# DDR32SS0_CTLPHY_WRAP_CTL_CFG_CTLCFG register map
Vendor: Texas Instruments
Registers are 32-bit, read-write, reset 0x0 unless marked. A register's access mark holds for its fields unless they carry their own. Offsets are as the file gives them; [hi:lo] are bit positions; lines under a group give offsets from that group; {n}, {i} and the like mark numbered series.

## DDR32SS0_CTLPHY_WRAP_CTL_CFG_CTLCFG (part 3 of 11)
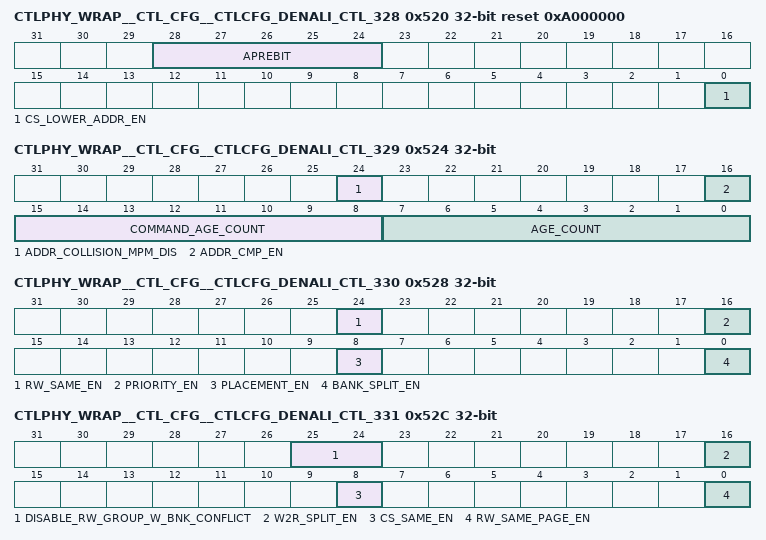
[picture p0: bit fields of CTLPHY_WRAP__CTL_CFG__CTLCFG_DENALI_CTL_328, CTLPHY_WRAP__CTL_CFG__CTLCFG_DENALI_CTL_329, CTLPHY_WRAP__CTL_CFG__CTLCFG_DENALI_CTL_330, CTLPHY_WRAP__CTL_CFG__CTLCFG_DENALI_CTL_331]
0x520 CTLPHY_WRAP__CTL_CFG__CTLCFG_DENALI_CTL_328 reset 0xA000000
  [28:24] APREBIT — Location of the auto pre-charge bit in the DRAM address.
  [0] CS_LOWER_ADDR_EN — Enables moving the CS field to lower in the address map. When set to 1, the memory address map will be changed to ROW__CS__BANK. Please refer to the limitations before setting this bit.
0x524 CTLPHY_WRAP__CTL_CFG__CTLCFG_DENALI_CTL_329
  [24] ADDR_COLLISION_MPM_DIS — Disable address collision detection extension using micro page mask for command queue placement and selection. Set to 1 to disable.
  [16] ADDR_CMP_EN — Enable address collision detection as a rule for command queue placement. Set to 1 to enable.
  [15:8] COMMAND_AGE_COUNT — Initial value of individual command aging counters for command aging.
  [7:0] AGE_COUNT — Initial value of controller aging-rate counter for command aging.
0x528 CTLPHY_WRAP__CTL_CFG__CTLCFG_DENALI_CTL_330
  [24] RW_SAME_EN — Enable read/write grouping as a rule for command queue placement. Set to 1 to enable.
  [16] PRIORITY_EN — Enable priority as a rule for command queue placement. Set to 1 to enable.
  [8] PLACEMENT_EN — Enable placement logic for command queue. Set to 1 to enable.
  [0] BANK_SPLIT_EN — Enable bank splitting as a rule for command queue placement. Set to 1 to enable.
0x52C CTLPHY_WRAP__CTL_CFG__CTLCFG_DENALI_CTL_331
  [25:24] DISABLE_RW_GROUP_W_BNK_CONFLICT — Disables placement to read/write group when grouping creates a bank collision. Bit [0] controls placement next to bank conflict command and bit [1] controls placement 2 away from bank conflict command. Set each bit to 1 to disable.
  [16] W2R_SPLIT_EN — Enable splitting of commands to the same chip select from a write to a read command as a rule for command queue placement.
  [8] CS_SAME_EN — Enable chip select grouping when read/write grouping as a rule for command queue placement. This is only valid when the RW_SAME_EN parameter is set. Set to 1 to enable.
  [0] RW_SAME_PAGE_EN — Enable page grouping when read/write grouping as a rule for command queue placement. This is only valid when the RW_SAME_EN parameter is set. Set to 1 to enable.
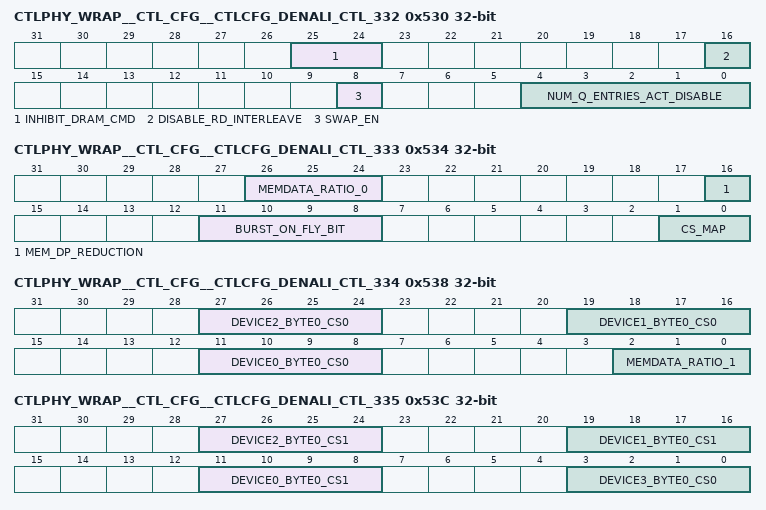
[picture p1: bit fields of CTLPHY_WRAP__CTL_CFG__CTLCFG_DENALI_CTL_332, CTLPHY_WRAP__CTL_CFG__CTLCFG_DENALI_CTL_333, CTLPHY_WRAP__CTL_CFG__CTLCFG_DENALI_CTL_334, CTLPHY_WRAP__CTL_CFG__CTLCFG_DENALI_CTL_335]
0x530 CTLPHY_WRAP__CTL_CFG__CTLCFG_DENALI_CTL_332
  [25:24] INHIBIT_DRAM_CMD — Inhibit command types from being executed from the command queue. Clear to 0 to enable any command, program to 1 to inhibit read/write and bank commands, program to 2 to inhibit MRR and peripheral MRR commands, or program to 3 to inhibit MRR and read/write commands.
  [16] DISABLE_RD_INTERLEAVE — Disable read data interleaving for commands from the same port, regardless of the requestor ID.
  [8] SWAP_EN — Enable command swapping logic in execution unit. Set to 1 to enable.
  [4:0] NUM_Q_ENTRIES_ACT_DISABLE — Number of queue entries in which ACT requests will be disabled. Programming to X will disable ACT requests from the X entries lowest in the command queue.
0x534 CTLPHY_WRAP__CTL_CFG__CTLCFG_DENALI_CTL_333
  [26:24] MEMDATA_RATIO_0 — Defines the ratio of the DRAM device size on chip select 0 to the memory data width. Program with the log2 ratio of the memory data width to the device data width. CS=0
  [16] MEM_DP_REDUCTION — Enable the half datapath feature of the controller. Set to 1 to enable.
  [11:8] BURST_ON_FLY_BIT — Identifies the burst-on-fly bit in the memory mode registers.
  [1:0] CS_MAP — Defines which chip selects are active.
0x538 CTLPHY_WRAP__CTL_CFG__CTLCFG_DENALI_CTL_334
  [27:24] DEVICE2_BYTE0_CS0 — Defines the byte location of byte0 in the memory datapath for device 2 on chip 0. Used for MRRs to identify where data will be returned. DEV=2
  [19:16] DEVICE1_BYTE0_CS0 — Defines the byte location of byte0 in the memory datapath for device 1 on chip 0. Used for MRRs to identify where data will be returned. DEV=1
  [11:8] DEVICE0_BYTE0_CS0 — Defines the byte location of byte0 in the memory datapath for device 0 on chip 0. Used for MRRs to identify where data will be returned. DEV=0
  [2:0] MEMDATA_RATIO_1 — Defines the ratio of the DRAM device size on chip select 1 to the memory data width. Program with the log2 ratio of the memory data width to the device data width. CS=1
0x53C CTLPHY_WRAP__CTL_CFG__CTLCFG_DENALI_CTL_335
  [27:24] DEVICE2_BYTE0_CS1 — Defines the byte location of byte0 in the memory datapath for device 2 on chip 1. Used for MRRs to identify where data will be returned. DEV=2
  [19:16] DEVICE1_BYTE0_CS1 — Defines the byte location of byte0 in the memory datapath for device 1 on chip 1. Used for MRRs to identify where data will be returned. DEV=1
  [11:8] DEVICE0_BYTE0_CS1 — Defines the byte location of byte0 in the memory datapath for device 0 on chip 1. Used for MRRs to identify where data will be returned. DEV=0
  [3:0] DEVICE3_BYTE0_CS0 — Defines the byte location of byte0 in the memory datapath for device 3 on chip 0. Used for MRRs to identify where data will be returned. DEV=3
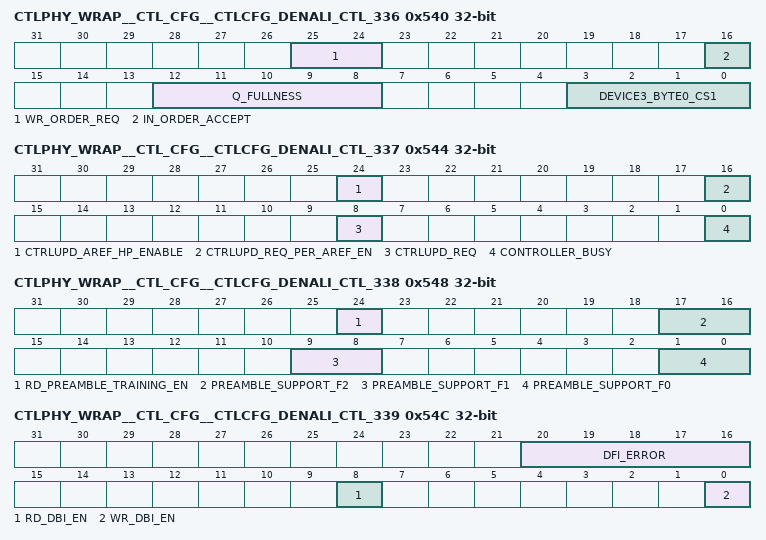
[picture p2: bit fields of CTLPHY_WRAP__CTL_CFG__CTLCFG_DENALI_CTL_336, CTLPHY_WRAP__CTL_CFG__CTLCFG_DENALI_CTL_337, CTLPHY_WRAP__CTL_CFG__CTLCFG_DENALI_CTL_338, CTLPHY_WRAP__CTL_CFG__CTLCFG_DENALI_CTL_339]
0x540 CTLPHY_WRAP__CTL_CFG__CTLCFG_DENALI_CTL_336
  [25:24] WR_ORDER_REQ — Determines if the controller can re-order write commands from the same source ID and/or the same port. Bit [0] controls source ID usage and bit [1] controls port ID usage. Set each bit to 1 to enable usage in placement logic.
  [16] IN_ORDER_ACCEPT — Forces the controller to accept commands in the order in which they are placed in the command queue.
  [12:8] Q_FULLNESS — Quantity that determines when the command queue almost full signal will assert [q_almost_full]. When cleared to 0, the q_almost_full signal will be driven to 0 irrespective of number of entries in the command queue.
  [3:0] DEVICE3_BYTE0_CS1 — Defines the byte location of byte0 in the memory datapath for device 3 on chip 1. Used for MRRs to identify where data will be returned. DEV=3
0x544 CTLPHY_WRAP__CTL_CFG__CTLCFG_DENALI_CTL_337 access per field
  [24] CTRLUPD_AREF_HP_ENABLE rw — Enable an automatic controller-initiated update [dfi_ctrlupd_req] after every high priority refresh when executing as a subtask request. Set to 1 to enable.
  [16] CTRLUPD_REQ_PER_AREF_EN rw — Enable an automatic controller-initiated update [dfi_ctrlupd_req] after every refresh. Set to 1 to enable.
  [8] CTRLUPD_REQ wo — Assert the DFI controller-initiated update request signal dfi_ctrlupd_req. Set to 1 to trigger. WRITE-ONLY
  [0] CONTROLLER_BUSY ro — Indicator that the controller is processing a command. Evaluates all ports for outstanding transactions. Value of 1 indicates controller busy. READ-ONLY
0x548 CTLPHY_WRAP__CTL_CFG__CTLCFG_DENALI_CTL_338
  [24] RD_PREAMBLE_TRAINING_EN — Enable read preamble training during gate training. Set to 1 to enable.
  [17:16] PREAMBLE_SUPPORT_F2 — Selection the preamble for read and write burst transfers. FC=2
  [9:8] PREAMBLE_SUPPORT_F1 — Selection the preamble for read and write burst transfers. FC=1
  [1:0] PREAMBLE_SUPPORT_F0 — Selection the preamble for read and write burst transfers. FC=0
0x54C CTLPHY_WRAP__CTL_CFG__CTLCFG_DENALI_CTL_339 access per field
  [20:16] DFI_ERROR ro — Indicates that the DFI error flag has been asserted. READ-ONLY
  [8] RD_DBI_EN rw — Enables controller support of DRAM DBI feature for read data with DDR4 devices. Set to 1 to enable.
  [0] WR_DBI_EN rw — Enables controller support of DRAM DBI feature for write data with DDR4 devices. Set to 1 to enable.
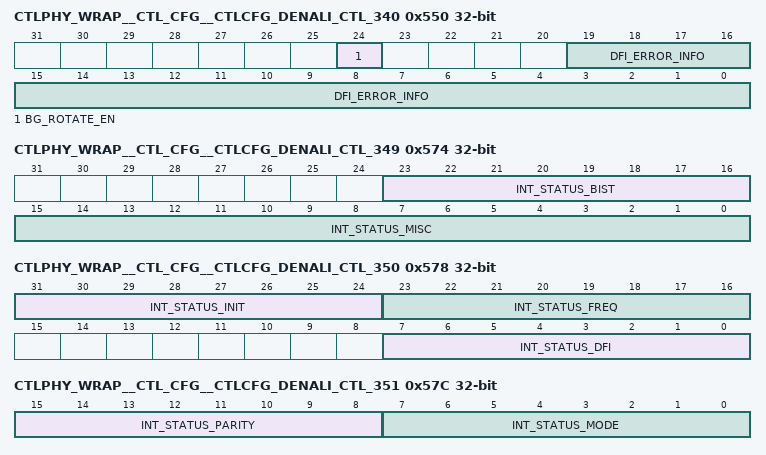
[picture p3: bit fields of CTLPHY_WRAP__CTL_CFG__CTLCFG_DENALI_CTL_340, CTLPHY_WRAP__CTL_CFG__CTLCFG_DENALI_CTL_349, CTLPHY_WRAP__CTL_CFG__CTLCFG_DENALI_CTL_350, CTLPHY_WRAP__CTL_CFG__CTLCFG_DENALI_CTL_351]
0x550 CTLPHY_WRAP__CTL_CFG__CTLCFG_DENALI_CTL_340 access per field
  [24] BG_ROTATE_EN rw — Enable bank group rotation. Set to 1 to enable.
  [19:0] DFI_ERROR_INFO ro — Holds the encoded DFI error type associated with the DFI_ERROR parameter assertion. READ-ONLY
0x554 CTLPHY_WRAP__CTL_CFG__CTLCFG_DENALI_CTL_341 access not given reset not defined
0x558 CTLPHY_WRAP__CTL_CFG__CTLCFG_DENALI_CTL_342 ro
  [31:0] INT_STATUS_MASTER — Controller status reporting register for interrupt status groups. READ-ONLY
0x55C CTLPHY_WRAP__CTL_CFG__CTLCFG_DENALI_CTL_343
  [31:0] INT_MASK_MASTER — Controller mask register for interrupt status groups. WRITE-ONLY
0x560 CTLPHY_WRAP__CTL_CFG__CTLCFG_DENALI_CTL_344 ro
  [31:0] INT_STATUS_TIMEOUT — Status of interrupts in the controller related to Timeout monitors. READ-ONLY
0x564 CTLPHY_WRAP__CTL_CFG__CTLCFG_DENALI_CTL_345 ro
  [31:16] INT_STATUS_LOWPOWER — Status of interrupts in the controller related to Low Power. READ-ONLY
0x568 CTLPHY_WRAP__CTL_CFG__CTLCFG_DENALI_CTL_346 access not given reset not defined
0x56C CTLPHY_WRAP__CTL_CFG__CTLCFG_DENALI_CTL_347 ro
  [31:0] INT_STATUS_TRAINING — Status of interrupts in the controller related to Training/Calibration. READ-ONLY
0x570 CTLPHY_WRAP__CTL_CFG__CTLCFG_DENALI_CTL_348 ro
  [31:0] INT_STATUS_USERIF — Status of interrupts in the controller related to ASIC to Controller Interface. READ-ONLY
0x574 CTLPHY_WRAP__CTL_CFG__CTLCFG_DENALI_CTL_349 ro
  [23:16] INT_STATUS_BIST — Status of interrupts in the controller related to BIST. READ-ONLY
  [15:0] INT_STATUS_MISC — Status of interrupts in the controller related to Miscellaneous features. READ-ONLY
0x578 CTLPHY_WRAP__CTL_CFG__CTLCFG_DENALI_CTL_350 ro
  [31:24] INT_STATUS_INIT — Status of interrupts in the controller related to Initialization. READ-ONLY
  [23:16] INT_STATUS_FREQ — Status of interrupts in the controller related to Frequency Scaling. READ-ONLY
  [7:0] INT_STATUS_DFI — Status of interrupts in the controller related to DFI. READ-ONLY
0x57C CTLPHY_WRAP__CTL_CFG__CTLCFG_DENALI_CTL_351 ro
  [15:8] INT_STATUS_PARITY — Status of interrupts in the controller related to Parity. READ-ONLY
  [7:0] INT_STATUS_MODE — Status of interrupts in the controller related to Memory Mode Settings. READ-ONLY
0x580 CTLPHY_WRAP__CTL_CFG__CTLCFG_DENALI_CTL_352 wo
  [31:0] INT_ACK_TIMEOUT — Clear status of the INT_STATUS_TIMEOUT parameter. WRITE-ONLY
0x584 CTLPHY_WRAP__CTL_CFG__CTLCFG_DENALI_CTL_353 wo
  [31:16] INT_ACK_LOWPOWER — Clear status of the INT_STATUS_LOWPOWER parameter. WRITE-ONLY
0x588 CTLPHY_WRAP__CTL_CFG__CTLCFG_DENALI_CTL_354 access not given reset not defined
0x58C CTLPHY_WRAP__CTL_CFG__CTLCFG_DENALI_CTL_355 wo
  [31:0] INT_ACK_TRAINING — Clear status of the INT_STATUS_TRAINING parameter. WRITE-ONLY
0x590 CTLPHY_WRAP__CTL_CFG__CTLCFG_DENALI_CTL_356 wo
  [31:0] INT_ACK_USERIF — Clear status of the INT_STATUS_USERIF parameter. WRITE-ONLY
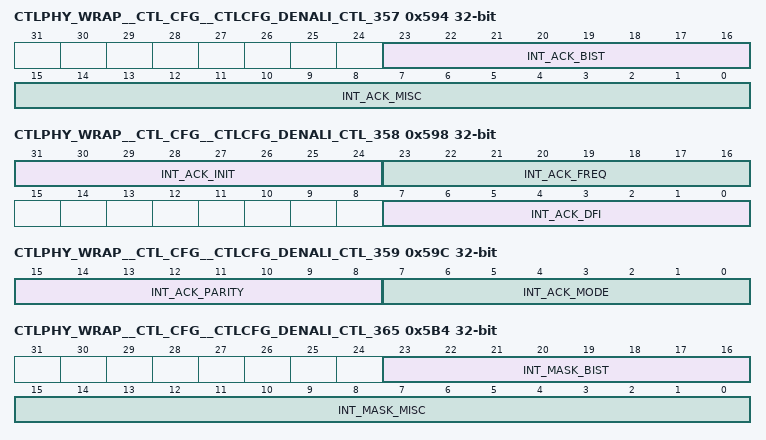
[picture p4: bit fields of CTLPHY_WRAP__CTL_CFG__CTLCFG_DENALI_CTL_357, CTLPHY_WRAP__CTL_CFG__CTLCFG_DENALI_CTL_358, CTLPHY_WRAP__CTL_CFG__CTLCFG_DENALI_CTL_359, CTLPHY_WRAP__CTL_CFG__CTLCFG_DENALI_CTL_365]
0x594 CTLPHY_WRAP__CTL_CFG__CTLCFG_DENALI_CTL_357 wo
  [23:16] INT_ACK_BIST — Clear status of the INT_STATUS_BIST parameter. WRITE-ONLY
  [15:0] INT_ACK_MISC — Clear status of the INT_STATUS_MISC parameter. WRITE-ONLY
0x598 CTLPHY_WRAP__CTL_CFG__CTLCFG_DENALI_CTL_358 wo
  [31:24] INT_ACK_INIT — Clear status of the INT_STATUS_INIT parameter. WRITE-ONLY
  [23:16] INT_ACK_FREQ — Clear status of the INT_STATUS_FREQ parameter. WRITE-ONLY
  [7:0] INT_ACK_DFI — Clear status of the INT_STATUS_DFI parameter. WRITE-ONLY
0x59C CTLPHY_WRAP__CTL_CFG__CTLCFG_DENALI_CTL_359 wo
  [15:8] INT_ACK_PARITY — Clear status of the INT_STATUS_PARITY parameter. WRITE-ONLY
  [7:0] INT_ACK_MODE — Clear status of the INT_STATUS_MODE parameter. WRITE-ONLY
0x5A0 CTLPHY_WRAP__CTL_CFG__CTLCFG_DENALI_CTL_360
  [31:0] INT_MASK_TIMEOUT — Mask for the controller_int signal from the INT_MASK_TIMEOUT parameter
0x5A4 CTLPHY_WRAP__CTL_CFG__CTLCFG_DENALI_CTL_361
  [31:16] INT_MASK_LOWPOWER — Mask for the controller_int signal from the INT_MASK_LOWPOWER parameter
0x5A8 CTLPHY_WRAP__CTL_CFG__CTLCFG_DENALI_CTL_362 access not given reset not defined
0x5AC CTLPHY_WRAP__CTL_CFG__CTLCFG_DENALI_CTL_363
  [31:0] INT_MASK_TRAINING — Mask for the controller_int signal from the INT_MASK_TRAINING parameter
0x5B0 CTLPHY_WRAP__CTL_CFG__CTLCFG_DENALI_CTL_364
  [31:0] INT_MASK_USERIF — Mask for the controller_int signal from the INT_MASK_USERIF parameter
0x5B4 CTLPHY_WRAP__CTL_CFG__CTLCFG_DENALI_CTL_365
  [23:16] INT_MASK_BIST — Mask for the controller_int signal from the INT_MASK_BIST parameter
  [15:0] INT_MASK_MISC — Mask for the controller_int signal from the INT_MASK_MISC parameter
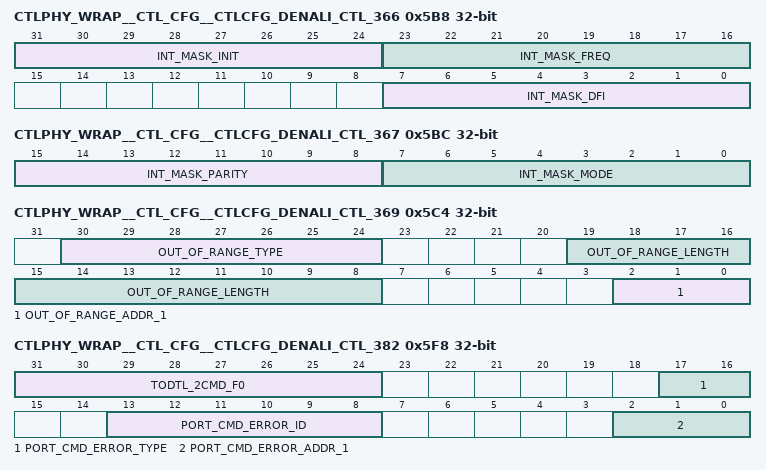
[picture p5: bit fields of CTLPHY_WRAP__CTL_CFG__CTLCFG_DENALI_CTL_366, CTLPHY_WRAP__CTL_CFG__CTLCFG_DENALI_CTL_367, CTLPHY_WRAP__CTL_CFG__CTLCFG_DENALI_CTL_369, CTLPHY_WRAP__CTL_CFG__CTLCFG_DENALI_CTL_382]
0x5B8 CTLPHY_WRAP__CTL_CFG__CTLCFG_DENALI_CTL_366
  [31:24] INT_MASK_INIT — Mask for the controller_int signal from the INT_MASK_INIT parameter
  [23:16] INT_MASK_FREQ — Mask for the controller_int signal from the INT_MASK_FREQ parameter
  [7:0] INT_MASK_DFI — Mask for the controller_int signal from the INT_MASK_DFI parameter
0x5BC CTLPHY_WRAP__CTL_CFG__CTLCFG_DENALI_CTL_367
  [15:8] INT_MASK_PARITY — Mask for the controller_int signal from the INT_MASK_PARITY parameter
  [7:0] INT_MASK_MODE — Mask for the controller_int signal from the INT_MASK_MODE parameter
0x5C0 CTLPHY_WRAP__CTL_CFG__CTLCFG_DENALI_CTL_368 ro
  [31:0] OUT_OF_RANGE_ADDR_0 — Address of command that caused an out-of-range interrupt. READ-ONLY
0x5C4 CTLPHY_WRAP__CTL_CFG__CTLCFG_DENALI_CTL_369 ro
  [30:24] OUT_OF_RANGE_TYPE — Type of command that caused an out-of-range interrupt. READ-ONLY
  [19:8] OUT_OF_RANGE_LENGTH — Length of command that caused an out-of-range interrupt. READ-ONLY
  [2:0] OUT_OF_RANGE_ADDR_1 — Address of command that caused an out-of-range interrupt. READ-ONLY
0x5C8 CTLPHY_WRAP__CTL_CFG__CTLCFG_DENALI_CTL_370 ro
  [5:0] OUT_OF_RANGE_SOURCE_ID — Source ID of command that caused an out-of-range interrupt. READ-ONLY
{0x0+4i} CTLPHY_WRAP__CTL_CFG__CTLCFG_DENALI_CTL_{i} ro (i=371..374)
  [31:0] BIST_EXP_DATA_{i-371} — Expected data on BIST error. READ-ONLY
{0x0+4i} CTLPHY_WRAP__CTL_CFG__CTLCFG_DENALI_CTL_{i} ro (i=375..378)
  [31:0] BIST_FAIL_DATA_{i-375} — Actual data on BIST error. READ-ONLY
0x5EC CTLPHY_WRAP__CTL_CFG__CTLCFG_DENALI_CTL_379 ro
  [31:0] BIST_FAIL_ADDR_0 — Address of BIST error. READ-ONLY
0x5F0 CTLPHY_WRAP__CTL_CFG__CTLCFG_DENALI_CTL_380 ro
  [2:0] BIST_FAIL_ADDR_1 — Address of BIST error. READ-ONLY
0x5F4 CTLPHY_WRAP__CTL_CFG__CTLCFG_DENALI_CTL_381 ro
  [31:0] PORT_CMD_ERROR_ADDR_0 — Address of command that caused the PORT command error. READ-ONLY
0x5F8 CTLPHY_WRAP__CTL_CFG__CTLCFG_DENALI_CTL_382 access per field
  [31:24] TODTL_2CMD_F0 rw — Defines the DRAM delay from an ODT de-assertion to the next non-write, non-read command. FC=0
  [17:16] PORT_CMD_ERROR_TYPE ro — Type of error and access type that caused the PORT command error. READ-ONLY
  [13:8] PORT_CMD_ERROR_ID ro — Source ID of command that caused the PORT command error. READ-ONLY
  [2:0] PORT_CMD_ERROR_ADDR_1 ro — Address of command that caused the PORT command error. READ-ONLY
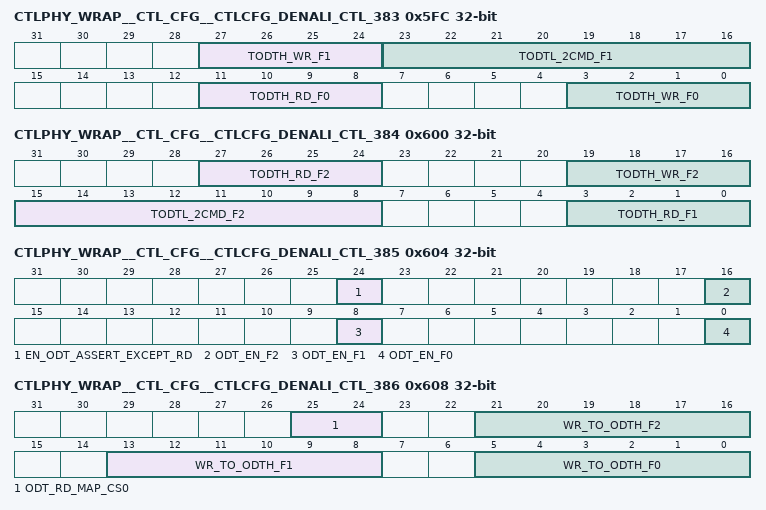
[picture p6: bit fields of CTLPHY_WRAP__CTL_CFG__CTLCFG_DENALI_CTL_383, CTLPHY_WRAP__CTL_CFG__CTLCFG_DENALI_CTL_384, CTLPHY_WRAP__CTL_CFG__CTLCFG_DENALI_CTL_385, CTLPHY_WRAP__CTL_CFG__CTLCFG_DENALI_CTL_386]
0x5FC CTLPHY_WRAP__CTL_CFG__CTLCFG_DENALI_CTL_383
  [27:24] TODTH_WR_F1 — Defines the DRAM minimum ODT high time after an ODT assertion for a write command. FC=1
  [23:16] TODTL_2CMD_F1 — Defines the DRAM delay from an ODT de-assertion to the next non-write, non-read command. FC=1
  [11:8] TODTH_RD_F0 — Defines the DRAM minimum ODT high time after an ODT assertion for a read command. FC=0
  [3:0] TODTH_WR_F0 — Defines the DRAM minimum ODT high time after an ODT assertion for a write command. FC=0
0x600 CTLPHY_WRAP__CTL_CFG__CTLCFG_DENALI_CTL_384
  [27:24] TODTH_RD_F2 — Defines the DRAM minimum ODT high time after an ODT assertion for a read command. FC=2
  [19:16] TODTH_WR_F2 — Defines the DRAM minimum ODT high time after an ODT assertion for a write command. FC=2
  [15:8] TODTL_2CMD_F2 — Defines the DRAM delay from an ODT de-assertion to the next non-write, non-read command. FC=2
  [3:0] TODTH_RD_F1 — Defines the DRAM minimum ODT high time after an ODT assertion for a read command. FC=1
0x604 CTLPHY_WRAP__CTL_CFG__CTLCFG_DENALI_CTL_385
  [24] EN_ODT_ASSERT_EXCEPT_RD — Enable controller to assert ODT at all times except during reads. Assumes single ODT pin connected. Set to 1 to enable.
  [16] ODT_EN_F2 — Enable support of DRAM ODT. When enabled, controller will assert and de-assert ODT output to DRAM as needed. FC=2
  [8] ODT_EN_F1 — Enable support of DRAM ODT. When enabled, controller will assert and de-assert ODT output to DRAM as needed. FC=1
  [0] ODT_EN_F0 — Enable support of DRAM ODT. When enabled, controller will assert and de-assert ODT output to DRAM as needed. FC=0
0x608 CTLPHY_WRAP__CTL_CFG__CTLCFG_DENALI_CTL_386
  [25:24] ODT_RD_MAP_CS0 — Determines which chip[s] will have termination when a read occurs. Set bit X to enable termination on csX when a read is performed. CS=0
  [21:16] WR_TO_ODTH_F2 — Defines the delay from a write command to ODT assertion. FC=2
  [13:8] WR_TO_ODTH_F1 — Defines the delay from a write command to ODT assertion. FC=1
  [5:0] WR_TO_ODTH_F0 — Defines the delay from a write command to ODT assertion. FC=0
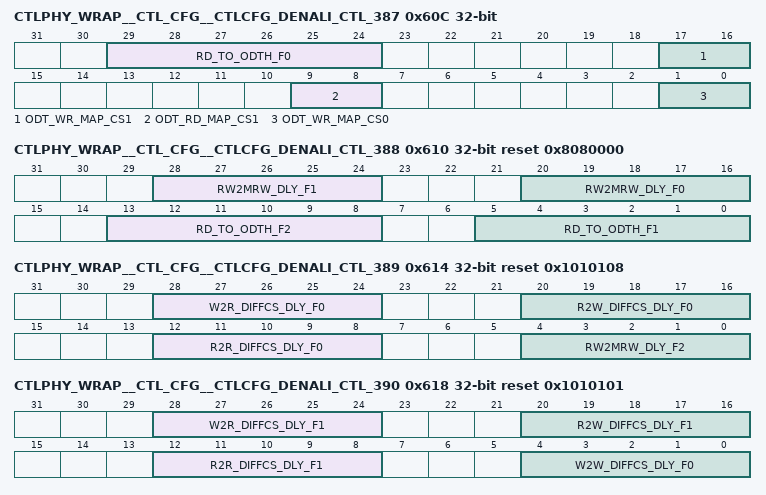
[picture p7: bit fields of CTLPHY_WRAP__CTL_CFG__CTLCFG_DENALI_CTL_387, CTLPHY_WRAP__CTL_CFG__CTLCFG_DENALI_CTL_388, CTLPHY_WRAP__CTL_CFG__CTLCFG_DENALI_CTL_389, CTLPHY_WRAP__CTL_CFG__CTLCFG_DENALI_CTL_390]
0x60C CTLPHY_WRAP__CTL_CFG__CTLCFG_DENALI_CTL_387
  [29:24] RD_TO_ODTH_F0 — Defines the delay from a read command to ODT assertion. FC=0
  [17:16] ODT_WR_MAP_CS1 — Determines which chip[s] will have termination when a write occurs. Set bit X to enable termination on csX when a write is performed. CS=1
  [9:8] ODT_RD_MAP_CS1 — Determines which chip[s] will have termination when a read occurs. Set bit X to enable termination on csX when a read is performed. CS=1
  [1:0] ODT_WR_MAP_CS0 — Determines which chip[s] will have termination when a write occurs. Set bit X to enable termination on csX when a write is performed. CS=0
0x610 CTLPHY_WRAP__CTL_CFG__CTLCFG_DENALI_CTL_388 reset 0x8080000
  [28:24] RW2MRW_DLY_F1 — Additional delay to insert between read or write and mode_reg_write. Allowed programming dependent on memory system. FC=1
  [20:16] RW2MRW_DLY_F0 — Additional delay to insert between read or write and mode_reg_write. Allowed programming dependent on memory system. FC=0
  [13:8] RD_TO_ODTH_F2 — Defines the delay from a read command to ODT assertion. FC=2
  [5:0] RD_TO_ODTH_F1 — Defines the delay from a read command to ODT assertion. FC=1
0x614 CTLPHY_WRAP__CTL_CFG__CTLCFG_DENALI_CTL_389 reset 0x1010108
  [28:24] W2R_DIFFCS_DLY_F0 — Additional delay to insert between writes and reads to different chip selects. Allowed programming dependent on memory system. FC=0
  [20:16] R2W_DIFFCS_DLY_F0 — Additional delay to insert between reads and writes to different chip selects. Program to a non-zero value. FC=0
  [12:8] R2R_DIFFCS_DLY_F0 — Additional delay to insert between reads to different chip selects. Program to a non-zero value. FC=0
  [4:0] RW2MRW_DLY_F2 — Additional delay to insert between read or write and mode_reg_write. Allowed programming dependent on memory system. FC=2
0x618 CTLPHY_WRAP__CTL_CFG__CTLCFG_DENALI_CTL_390 reset 0x1010101
  [28:24] W2R_DIFFCS_DLY_F1 — Additional delay to insert between writes and reads to different chip selects. Allowed programming dependent on memory system. FC=1
  [20:16] R2W_DIFFCS_DLY_F1 — Additional delay to insert between reads and writes to different chip selects. Program to a non-zero value. FC=1
  [12:8] R2R_DIFFCS_DLY_F1 — Additional delay to insert between reads to different chip selects. Program to a non-zero value. FC=1
  [4:0] W2W_DIFFCS_DLY_F0 — Additional delay to insert between writes to different chip selects. Program to a non-zero value. FC=0
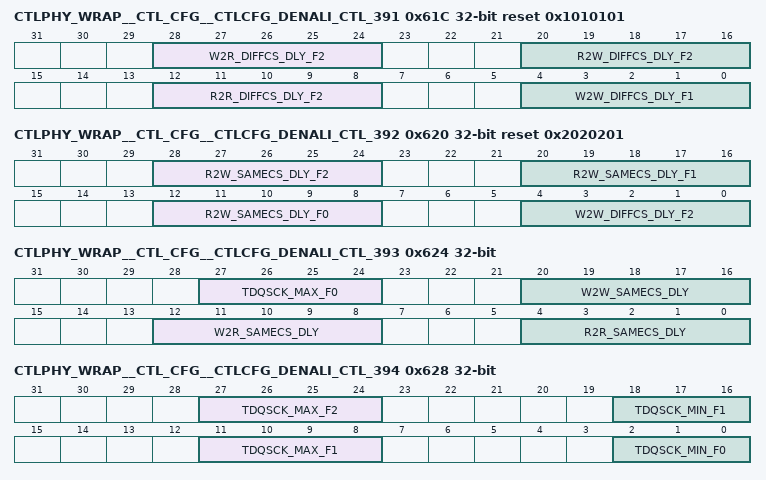
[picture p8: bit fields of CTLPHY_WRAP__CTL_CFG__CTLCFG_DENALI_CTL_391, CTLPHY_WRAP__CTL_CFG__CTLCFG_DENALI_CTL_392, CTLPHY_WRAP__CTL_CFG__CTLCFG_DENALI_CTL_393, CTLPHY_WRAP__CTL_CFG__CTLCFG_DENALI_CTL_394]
0x61C CTLPHY_WRAP__CTL_CFG__CTLCFG_DENALI_CTL_391 reset 0x1010101
  [28:24] W2R_DIFFCS_DLY_F2 — Additional delay to insert between writes and reads to different chip selects. Allowed programming dependent on memory system. FC=2
  [20:16] R2W_DIFFCS_DLY_F2 — Additional delay to insert between reads and writes to different chip selects. Program to a non-zero value. FC=2
  [12:8] R2R_DIFFCS_DLY_F2 — Additional delay to insert between reads to different chip selects. Program to a non-zero value. FC=2
  [4:0] W2W_DIFFCS_DLY_F1 — Additional delay to insert between writes to different chip selects. Program to a non-zero value. FC=1
0x620 CTLPHY_WRAP__CTL_CFG__CTLCFG_DENALI_CTL_392 reset 0x2020201
  [28:24] R2W_SAMECS_DLY_F2 — Additional delay to insert between reads and writes to the same chip select. Program to a non-zero value. FC=2
  [20:16] R2W_SAMECS_DLY_F1 — Additional delay to insert between reads and writes to the same chip select. Program to a non-zero value. FC=1
  [12:8] R2W_SAMECS_DLY_F0 — Additional delay to insert between reads and writes to the same chip select. Program to a non-zero value. FC=0
  [4:0] W2W_DIFFCS_DLY_F2 — Additional delay to insert between writes to different chip selects. Program to a non-zero value. FC=2
0x624 CTLPHY_WRAP__CTL_CFG__CTLCFG_DENALI_CTL_393
  [27:24] TDQSCK_MAX_F0 — Additional delay needed for tDQSCK. FC=0
  [20:16] W2W_SAMECS_DLY — Additional delay to insert between two writes to the same chip select. Any value including 0 supported.
  [12:8] W2R_SAMECS_DLY — Additional delay to insert between writes and reads to the same chip select.
  [4:0] R2R_SAMECS_DLY — Additional delay to insert between two reads to the same chip select. Any value including 0 supported.
0x628 CTLPHY_WRAP__CTL_CFG__CTLCFG_DENALI_CTL_394
  [27:24] TDQSCK_MAX_F2 — Additional delay needed for tDQSCK. FC=2
  [18:16] TDQSCK_MIN_F1 — Additional delay needed for tDQSCK. FC=1
  [11:8] TDQSCK_MAX_F1 — Additional delay needed for tDQSCK. FC=1
  [2:0] TDQSCK_MIN_F0 — Additional delay needed for tDQSCK. FC=0
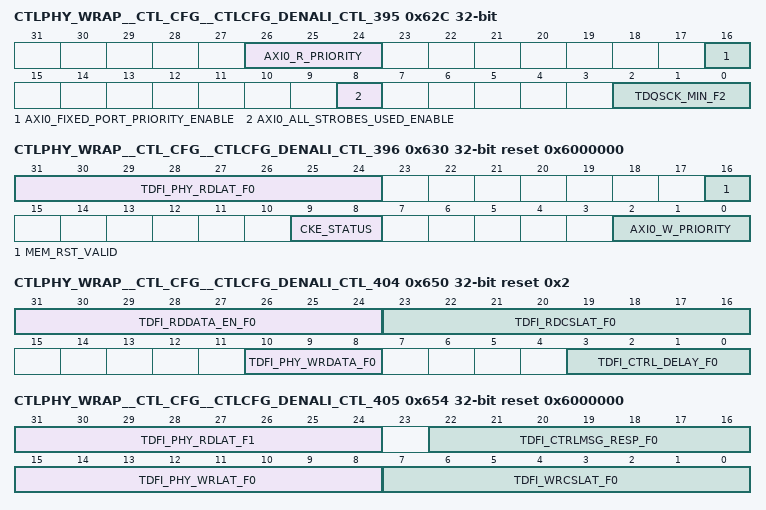
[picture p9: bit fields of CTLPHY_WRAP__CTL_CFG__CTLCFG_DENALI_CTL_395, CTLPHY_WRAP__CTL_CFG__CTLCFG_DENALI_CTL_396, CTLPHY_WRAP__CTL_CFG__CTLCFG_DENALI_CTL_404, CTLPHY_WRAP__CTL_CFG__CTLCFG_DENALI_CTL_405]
0x62C CTLPHY_WRAP__CTL_CFG__CTLCFG_DENALI_CTL_395
  [26:24] AXI0_R_PRIORITY — Priority of read commands from AXI port 0. 0 is the highest priority. This may only be changed before initialization begins or when the controller is quiescent, there is no data in the port FIFOs, and the AXI0_FIXED_PORT_PRIORITY_ENABLE parameter is low.
  [16] AXI0_FIXED_PORT_PRIORITY_ENABLE — Defines the priority control for AXI port 0 as per-port or per-command. Set to 1 for per-port with priority defined through the AXI.0._R_PRIORITY and AXI.0._W_PRIORITY parameters. Clear to 0 for per-command.
  [8] AXI0_ALL_STROBES_USED_ENABLE — Enables use of the AWALLSTRB signal for AXI port 0. Set to 1 to enable.
  [2:0] TDQSCK_MIN_F2 — Additional delay needed for tDQSCK. FC=2
0x630 CTLPHY_WRAP__CTL_CFG__CTLCFG_DENALI_CTL_396 access per field reset 0x6000000
  [31:24] TDFI_PHY_RDLAT_F0 rw — Defines the DFI tPHY_RDLAT timing parameter [in DFI PHY clocks], the maximum cycles between a dfi_rddata_en assertion and a dfi_rddata_valid assertion. FC=0
  [16] MEM_RST_VALID ro — Register access to mem_rst_valid signal. READ-ONLY
  [9:8] CKE_STATUS ro — Register access to cke_status signal. READ-ONLY
  [2:0] AXI0_W_PRIORITY rw — Priority of write commands from AXI port 0. 0 is the highest priority. This may only be changed before initialization begins or when the controller is quiescent, there is no data in the port FIFOs, and the AXI0_FIXED_PORT_PRIORITY_ENABLE parameter is low.
0x634 CTLPHY_WRAP__CTL_CFG__CTLCFG_DENALI_CTL_397
  [20:0] TDFI_CTRLUPD_MAX_F0 — Defines the DFI tCTRLUPD_MAX timing parameter [in DFI clocks], the maximum cycles that dfi_ctrlupd_req can be asserted. If programmed to a non-zero, a timing violation will cause an interrupt and bit [0] set in the UPDATE_ERROR_STATUS parameter. FC=0
{0x0+4i} CTLPHY_WRAP__CTL_CFG__CTLCFG_DENALI_CTL_{i} (i=398..401)
  [31:0] TDFI_PHYUPD_TYPE{i-398}_F0 — Defines the DFI tPHYUPD_TYPE{i-398} timing parameter [in DFI clocks], the maximum cycles that dfi_phyupd_req can assert after dfi_phyupd_ack for dfi_phyupd_type {i-398}. If programmed to a non-zero, a timing violation will cause an interrupt and bit [{i-397}] set in the UPDATE_ERROR_STATUS parameter. FC=0
0x648 CTLPHY_WRAP__CTL_CFG__CTLCFG_DENALI_CTL_402
  [22:0] TDFI_PHYUPD_RESP_F0 — Defines the DFI tPHYUPD_RESP timing parameter [in DFI clocks], the maximum cycles between a dfi_phyupd_req assertion and a dfi_phyupd_ack assertion. If programmed to a non-zero, a timing violation will cause an interrupt and bit [5] set in the UPDATE_ERROR_STATUS parameter. FC=0
0x64C CTLPHY_WRAP__CTL_CFG__CTLCFG_DENALI_CTL_403
  [31:0] TDFI_CTRLUPD_INTERVAL_F0 — Defines the DFI tCTRLUPD_INTERVAL timing parameter [in DFI clocks], the maximum cycles between dfi_ctrlupd_req assertions. If programmed to a non-zero, a timing violation will cause an interrupt and bit [6] set in the UPDATE_ERROR_STATUS parameter. FC=0
0x650 CTLPHY_WRAP__CTL_CFG__CTLCFG_DENALI_CTL_404 reset 0x2
  [31:24] TDFI_RDDATA_EN_F0 — DFI tRDDATA_EN timing parameter. This is the number of DFI data phases between a read command and the first assertion of dfi_rddata_en_pN. FC=0
  [23:16] TDFI_RDCSLAT_F0 — Defines the DFI tPHY_RDCSLAT timing parameter [in DFI PHY clocks], the maximum cycles between a read command and a dfi_rddata_cs_n assertion. FC=0
  [10:8] TDFI_PHY_WRDATA_F0 — Defines the DFI tPHY_WRDATA timing parameter [in DFI PHY clocks], the maximum cycles between a dfi_wrdata_en assertion and a dfi_wrdata signal. FC=0
  [3:0] TDFI_CTRL_DELAY_F0 — Defines the DFI tCTRL_DELAY timing parameter [in DFI clocks], the delay between a DFI command change and a memory command. FC=0
0x654 CTLPHY_WRAP__CTL_CFG__CTLCFG_DENALI_CTL_405 reset 0x6000000
  [31:24] TDFI_PHY_RDLAT_F1 — Defines the DFI tPHY_RDLAT timing parameter [in DFI PHY clocks], the maximum cycles between a dfi_rddata_en assertion and a dfi_rddata_valid assertion. FC=1
  [22:16] TDFI_CTRLMSG_RESP_F0 — Defines the DFI tCTRLMSG_RESP timing parameter [in DFI clocks], the maximum number of DFI clocks allowed for dfi_ctrlmsg_ack to assert after dfi_ctrlmsg_req goes high. FC=0
  [15:8] TDFI_PHY_WRLAT_F0 — DFI tPHY_WRLAT timing parameter. This is the number of DFI data phases between a write command and the first assertion of dfi_wrdata_en_pN. FC=0
  [7:0] TDFI_WRCSLAT_F0 — Defines the DFI tPHY_WRCSLAT timing parameter [in DFI PHY clocks], the maximum cycles between a write command and a dfi_wrdata_cs_n assertion. FC=0
0x658 CTLPHY_WRAP__CTL_CFG__CTLCFG_DENALI_CTL_406
  [20:0] TDFI_CTRLUPD_MAX_F1 — Defines the DFI tCTRLUPD_MAX timing parameter [in DFI clocks], the maximum cycles that dfi_ctrlupd_req can be asserted. If programmed to a non-zero, a timing violation will cause an interrupt and bit [0] set in the UPDATE_ERROR_STATUS parameter. FC=1
{0x0+4i} CTLPHY_WRAP__CTL_CFG__CTLCFG_DENALI_CTL_{i} (i=407..410)
  [31:0] TDFI_PHYUPD_TYPE{i-407}_F1 — Defines the DFI tPHYUPD_TYPE{i-407} timing parameter [in DFI clocks], the maximum cycles that dfi_phyupd_req can assert after dfi_phyupd_ack for dfi_phyupd_type {i-407}. If programmed to a non-zero, a timing violation will cause an interrupt and bit [{i-406}] set in the UPDATE_ERROR_STATUS parameter. FC=1
0x66C CTLPHY_WRAP__CTL_CFG__CTLCFG_DENALI_CTL_411
  [22:0] TDFI_PHYUPD_RESP_F1 — Defines the DFI tPHYUPD_RESP timing parameter [in DFI clocks], the maximum cycles between a dfi_phyupd_req assertion and a dfi_phyupd_ack assertion. If programmed to a non-zero, a timing violation will cause an interrupt and bit [5] set in the UPDATE_ERROR_STATUS parameter. FC=1
0x670 CTLPHY_WRAP__CTL_CFG__CTLCFG_DENALI_CTL_412
  [31:0] TDFI_CTRLUPD_INTERVAL_F1 — Defines the DFI tCTRLUPD_INTERVAL timing parameter [in DFI clocks], the maximum cycles between dfi_ctrlupd_req assertions. If programmed to a non-zero, a timing violation will cause an interrupt and bit [6] set in the UPDATE_ERROR_STATUS parameter. FC=1
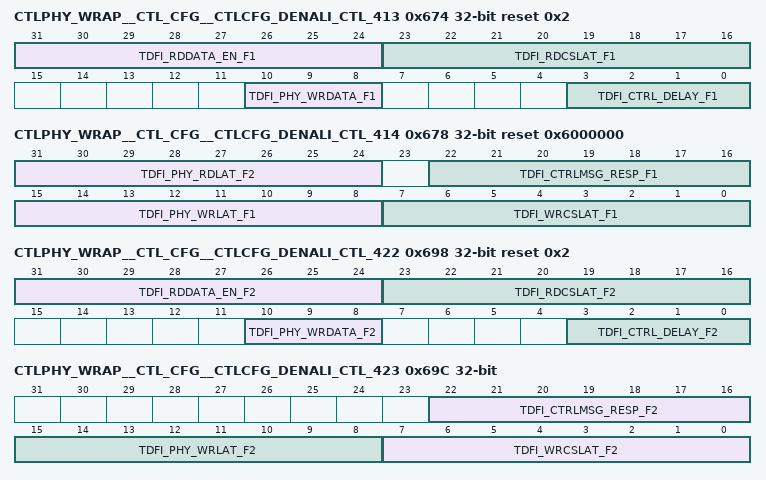
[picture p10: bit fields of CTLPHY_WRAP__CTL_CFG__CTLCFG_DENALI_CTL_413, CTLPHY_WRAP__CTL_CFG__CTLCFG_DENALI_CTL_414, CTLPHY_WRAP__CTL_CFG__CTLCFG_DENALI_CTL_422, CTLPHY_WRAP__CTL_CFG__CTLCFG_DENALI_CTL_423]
0x674 CTLPHY_WRAP__CTL_CFG__CTLCFG_DENALI_CTL_413 reset 0x2
  [31:24] TDFI_RDDATA_EN_F1 — DFI tRDDATA_EN timing parameter. This is the number of DFI data phases between a read command and the first assertion of dfi_rddata_en_pN. FC=1
  [23:16] TDFI_RDCSLAT_F1 — Defines the DFI tPHY_RDCSLAT timing parameter [in DFI PHY clocks], the maximum cycles between a read command and a dfi_rddata_cs_n assertion. FC=1
  [10:8] TDFI_PHY_WRDATA_F1 — Defines the DFI tPHY_WRDATA timing parameter [in DFI PHY clocks], the maximum cycles between a dfi_wrdata_en assertion and a dfi_wrdata signal. FC=1
  [3:0] TDFI_CTRL_DELAY_F1 — Defines the DFI tCTRL_DELAY timing parameter [in DFI clocks], the delay between a DFI command change and a memory command. FC=1
0x678 CTLPHY_WRAP__CTL_CFG__CTLCFG_DENALI_CTL_414 reset 0x6000000
  [31:24] TDFI_PHY_RDLAT_F2 — Defines the DFI tPHY_RDLAT timing parameter [in DFI PHY clocks], the maximum cycles between a dfi_rddata_en assertion and a dfi_rddata_valid assertion. FC=2
  [22:16] TDFI_CTRLMSG_RESP_F1 — Defines the DFI tCTRLMSG_RESP timing parameter [in DFI clocks], the maximum number of DFI clocks allowed for dfi_ctrlmsg_ack to assert after dfi_ctrlmsg_req goes high. FC=1
  [15:8] TDFI_PHY_WRLAT_F1 — DFI tPHY_WRLAT timing parameter. This is the number of DFI data phases between a write command and the first assertion of dfi_wrdata_en_pN. FC=1
  [7:0] TDFI_WRCSLAT_F1 — Defines the DFI tPHY_WRCSLAT timing parameter [in DFI PHY clocks], the maximum cycles between a write command and a dfi_wrdata_cs_n assertion. FC=1
0x67C CTLPHY_WRAP__CTL_CFG__CTLCFG_DENALI_CTL_415
  [20:0] TDFI_CTRLUPD_MAX_F2 — Defines the DFI tCTRLUPD_MAX timing parameter [in DFI clocks], the maximum cycles that dfi_ctrlupd_req can be asserted. If programmed to a non-zero, a timing violation will cause an interrupt and bit [0] set in the UPDATE_ERROR_STATUS parameter. FC=2
{0x0+4i} CTLPHY_WRAP__CTL_CFG__CTLCFG_DENALI_CTL_{i} (i=416..419)
  [31:0] TDFI_PHYUPD_TYPE{i-416}_F2 — Defines the DFI tPHYUPD_TYPE{i-416} timing parameter [in DFI clocks], the maximum cycles that dfi_phyupd_req can assert after dfi_phyupd_ack for dfi_phyupd_type {i-416}. If programmed to a non-zero, a timing violation will cause an interrupt and bit [{i-415}] set in the UPDATE_ERROR_STATUS parameter. FC=2
0x690 CTLPHY_WRAP__CTL_CFG__CTLCFG_DENALI_CTL_420
  [22:0] TDFI_PHYUPD_RESP_F2 — Defines the DFI tPHYUPD_RESP timing parameter [in DFI clocks], the maximum cycles between a dfi_phyupd_req assertion and a dfi_phyupd_ack assertion. If programmed to a non-zero, a timing violation will cause an interrupt and bit [5] set in the UPDATE_ERROR_STATUS parameter. FC=2
0x694 CTLPHY_WRAP__CTL_CFG__CTLCFG_DENALI_CTL_421
  [31:0] TDFI_CTRLUPD_INTERVAL_F2 — Defines the DFI tCTRLUPD_INTERVAL timing parameter [in DFI clocks], the maximum cycles between dfi_ctrlupd_req assertions. If programmed to a non-zero, a timing violation will cause an interrupt and bit [6] set in the UPDATE_ERROR_STATUS parameter. FC=2
0x698 CTLPHY_WRAP__CTL_CFG__CTLCFG_DENALI_CTL_422 reset 0x2
  [31:24] TDFI_RDDATA_EN_F2 — DFI tRDDATA_EN timing parameter. This is the number of DFI data phases between a read command and the first assertion of dfi_rddata_en_pN. FC=2
  [23:16] TDFI_RDCSLAT_F2 — Defines the DFI tPHY_RDCSLAT timing parameter [in DFI PHY clocks], the maximum cycles between a read command and a dfi_rddata_cs_n assertion. FC=2
  [10:8] TDFI_PHY_WRDATA_F2 — Defines the DFI tPHY_WRDATA timing parameter [in DFI PHY clocks], the maximum cycles between a dfi_wrdata_en assertion and a dfi_wrdata signal. FC=2
  [3:0] TDFI_CTRL_DELAY_F2 — Defines the DFI tCTRL_DELAY timing parameter [in DFI clocks], the delay between a DFI command change and a memory command. FC=2
0x69C CTLPHY_WRAP__CTL_CFG__CTLCFG_DENALI_CTL_423
  [22:16] TDFI_CTRLMSG_RESP_F2 — Defines the DFI tCTRLMSG_RESP timing parameter [in DFI clocks], the maximum number of DFI clocks allowed for dfi_ctrlmsg_ack to assert after dfi_ctrlmsg_req goes high. FC=2
  [15:8] TDFI_PHY_WRLAT_F2 — DFI tPHY_WRLAT timing parameter. This is the number of DFI data phases between a write command and the first assertion of dfi_wrdata_en_pN. FC=2
  [7:0] TDFI_WRCSLAT_F2 — Defines the DFI tPHY_WRCSLAT timing parameter [in DFI PHY clocks], the maximum cycles between a write command and a dfi_wrdata_cs_n assertion. FC=2
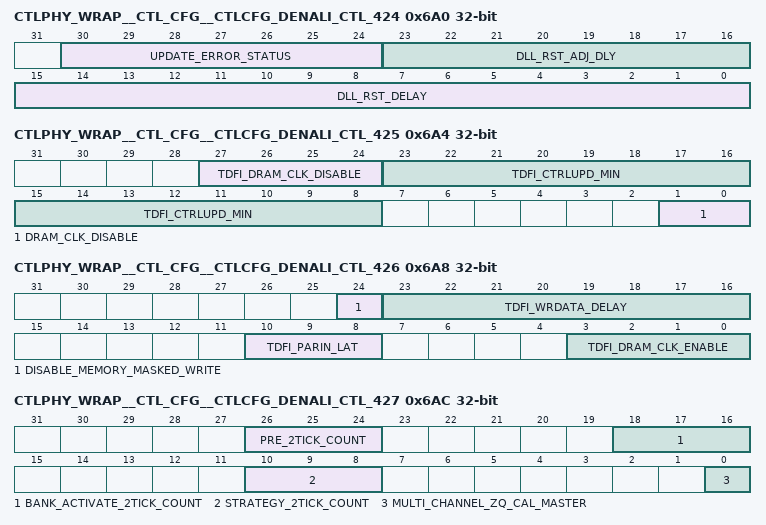
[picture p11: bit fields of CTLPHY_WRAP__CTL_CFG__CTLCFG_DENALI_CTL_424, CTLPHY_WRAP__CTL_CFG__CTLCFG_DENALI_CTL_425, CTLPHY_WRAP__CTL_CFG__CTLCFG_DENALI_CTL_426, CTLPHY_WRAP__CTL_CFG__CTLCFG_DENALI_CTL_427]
0x6A0 CTLPHY_WRAP__CTL_CFG__CTLCFG_DENALI_CTL_424 access per field
  [30:24] UPDATE_ERROR_STATUS ro — Identifies the source of any DFI MC-initiated or PHY-initiated update errors. Value of 1 indicates a timing violation of the associated timing parameter. READ-ONLY
  [23:16] DLL_RST_ADJ_DLY rw — Minimum cycles after setting controller delay in DLL until the DLL reset signal dll_rst_n may be asserted. If this signal is not being used by the PHY, this parameter may be ignored.
  [15:0] DLL_RST_DELAY rw — Minimum cycles required for DLL reset signal dll_rst_n to be held. If this signal is not being used by the PHY, this parameter may be ignored.
0x6A4 CTLPHY_WRAP__CTL_CFG__CTLCFG_DENALI_CTL_425
  [27:24] TDFI_DRAM_CLK_DISABLE — Defines the DFI tDRAM_CLK_DISABLE timing parameter [in DFI clocks], the delay between a dfi_dram_clock_disable assertion and the memory clock disable.
  [23:8] TDFI_CTRLUPD_MIN — Defines the DFI tCTRLUPD_MIN timing parameter [in DFI clocks], the minimum cycles that dfi_ctrlupd_req must be asserted.
  [1:0] DRAM_CLK_DISABLE — Set value for the dfi_dram_clk_disable signal. Bit [0] controls cs0, bit [1] controls cs1, etc. Set each bit to 1 to disable.
0x6A8 CTLPHY_WRAP__CTL_CFG__CTLCFG_DENALI_CTL_426
  [24] DISABLE_MEMORY_MASKED_WRITE — Restricts the controller from masked write commands. Set to 1 to not issue these commands. Only used if connected to an LPDDR4 device.
  [23:16] TDFI_WRDATA_DELAY — Defines the tWRDATA_DELAY timing parameter [in DFI PHY clocks], the maximum cycles between when the dfi_wrdata_en signal is asserted and when the corresponding write data transfer is completed on the DRAM bus.
  [10:8] TDFI_PARIN_LAT — Defines the DFI tPARIN_LAT timing parameter [in DFI PHY clocks], the maximum cycles between a DFI command and a dfi_parity_in signal assertion.
  [3:0] TDFI_DRAM_CLK_ENABLE — Defines the DFI tDRAM_CLK_ENABLE timing parameter [in DFI clocks], the delay between a dfi_dram_clk_disable de-assertion and the memory clock enable.
0x6AC CTLPHY_WRAP__CTL_CFG__CTLCFG_DENALI_CTL_427
  [26:24] PRE_2TICK_COUNT — NEED TO FiLL IN .
  [18:16] BANK_ACTIVATE_2TICK_COUNT — NEED TO FiLL IN .
  [10:8] STRATEGY_2TICK_COUNT — NEED TO FiLL IN .
  [0] MULTI_CHANNEL_ZQ_CAL_MASTER — In a two controller scenario, defines if this controller will issue ZQ calibration start commands when neither controller is in a low power mode. Set to 1 to define this controller as the controller that issues ZQ calibration start commands or clear to 0 to define this controller as the target. This parameter should only be programmed once during initialization.
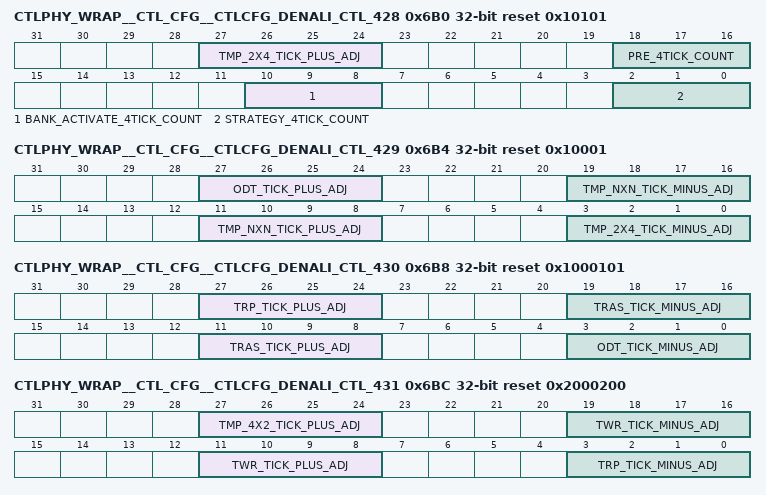
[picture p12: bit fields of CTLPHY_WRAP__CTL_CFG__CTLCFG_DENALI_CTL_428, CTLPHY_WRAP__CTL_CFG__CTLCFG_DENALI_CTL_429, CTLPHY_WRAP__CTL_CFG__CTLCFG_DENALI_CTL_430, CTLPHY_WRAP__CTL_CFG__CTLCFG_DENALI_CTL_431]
0x6B0 CTLPHY_WRAP__CTL_CFG__CTLCFG_DENALI_CTL_428 reset 0x10101
  [27:24] TMP_2X4_TICK_PLUS_ADJ — NEED TO FiLL IN .
  [18:16] PRE_4TICK_COUNT — NEED TO FiLL IN .
  [10:8] BANK_ACTIVATE_4TICK_COUNT — NEED TO FiLL IN .
  [2:0] STRATEGY_4TICK_COUNT — NEED TO FiLL IN .
0x6B4 CTLPHY_WRAP__CTL_CFG__CTLCFG_DENALI_CTL_429 reset 0x10001
  [27:24] ODT_TICK_PLUS_ADJ — NEED TO FiLL IN .
  [19:16] TMP_NXN_TICK_MINUS_ADJ — NEED TO FiLL IN .
  [11:8] TMP_NXN_TICK_PLUS_ADJ — NEED TO FiLL IN .
  [3:0] TMP_2X4_TICK_MINUS_ADJ — NEED TO FiLL IN .
0x6B8 CTLPHY_WRAP__CTL_CFG__CTLCFG_DENALI_CTL_430 reset 0x1000101
  [27:24] TRP_TICK_PLUS_ADJ — NEED TO FiLL IN .
  [19:16] TRAS_TICK_MINUS_ADJ — NEED TO FiLL IN .
  [11:8] TRAS_TICK_PLUS_ADJ — NEED TO FiLL IN .
  [3:0] ODT_TICK_MINUS_ADJ — NEED TO FiLL IN .
0x6BC CTLPHY_WRAP__CTL_CFG__CTLCFG_DENALI_CTL_431 reset 0x2000200
  [27:24] TMP_4X2_TICK_PLUS_ADJ — NEED TO FiLL IN .
  [19:16] TWR_TICK_MINUS_ADJ — NEED TO FiLL IN .
  [11:8] TWR_TICK_PLUS_ADJ — NEED TO FiLL IN .
  [3:0] TRP_TICK_MINUS_ADJ — NEED TO FiLL IN .
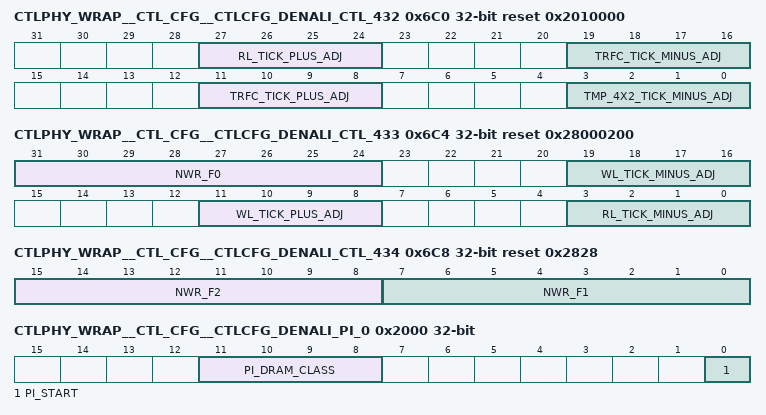
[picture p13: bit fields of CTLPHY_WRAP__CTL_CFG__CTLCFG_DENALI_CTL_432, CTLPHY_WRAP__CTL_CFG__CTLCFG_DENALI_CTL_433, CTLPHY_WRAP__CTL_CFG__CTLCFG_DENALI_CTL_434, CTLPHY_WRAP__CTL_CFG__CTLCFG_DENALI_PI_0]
0x6C0 CTLPHY_WRAP__CTL_CFG__CTLCFG_DENALI_CTL_432 reset 0x2010000
  [27:24] RL_TICK_PLUS_ADJ — NEED TO FiLL IN .
  [19:16] TRFC_TICK_MINUS_ADJ — NEED TO FiLL IN .
  [11:8] TRFC_TICK_PLUS_ADJ — NEED TO FiLL IN .
  [3:0] TMP_4X2_TICK_MINUS_ADJ — NEED TO FiLL IN .
0x6C4 CTLPHY_WRAP__CTL_CFG__CTLCFG_DENALI_CTL_433 reset 0x28000200
  [31:24] NWR_F0 — DRAM NWR value in cycles. FC=0
  [19:16] WL_TICK_MINUS_ADJ — NEED TO FiLL IN .
  [11:8] WL_TICK_PLUS_ADJ — NEED TO FiLL IN .
  [3:0] RL_TICK_MINUS_ADJ — NEED TO FiLL IN .
0x6C8 CTLPHY_WRAP__CTL_CFG__CTLCFG_DENALI_CTL_434 reset 0x2828
  [15:8] NWR_F2 — DRAM NWR value in cycles. FC=2
  [7:0] NWR_F1 — DRAM NWR value in cycles. FC=1
0x2000 CTLPHY_WRAP__CTL_CFG__CTLCFG_DENALI_PI_0
  [11:8] PI_DRAM_CLASS — Defines the memory class for the PI.
  [0] PI_START — Initiate command processing in the PI. Set to 1 to initiate.
0x2004 CTLPHY_WRAP__CTL_CFG__CTLCFG_DENALI_PI_1 ro reset 0x30BD08BA
  [31:0] PI_VERSION_0 — Holds the PI version number. This is a unique number for each PHY IP delivery. This will help in identifying different version of the PHY IP. READ-ONLY
0x2008 CTLPHY_WRAP__CTL_CFG__CTLCFG_DENALI_PI_2 ro reset 0x453CB5C
  [31:0] PI_VERSION_1 — Holds the PI version number. This is a unique number for each PHY IP delivery. This will help in identifying different version of the PHY IP. READ-ONLY
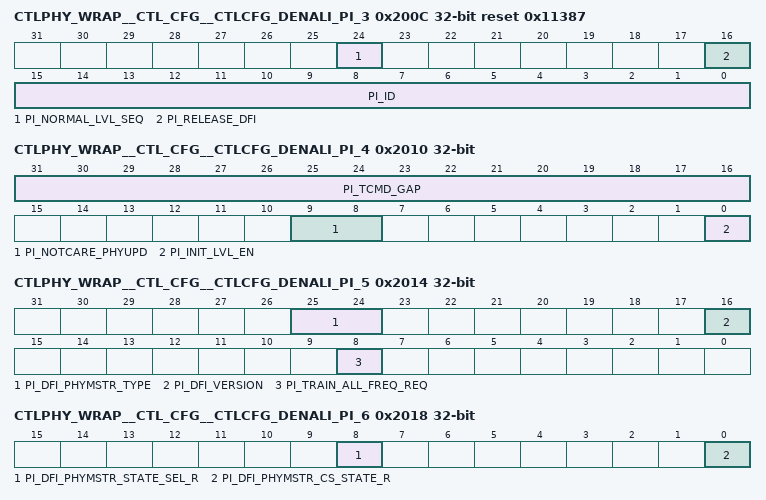
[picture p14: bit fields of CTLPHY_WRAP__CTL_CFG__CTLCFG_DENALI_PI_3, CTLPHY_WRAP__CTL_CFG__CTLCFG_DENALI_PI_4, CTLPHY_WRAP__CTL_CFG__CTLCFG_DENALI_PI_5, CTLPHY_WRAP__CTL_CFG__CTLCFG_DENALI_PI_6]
0x200C CTLPHY_WRAP__CTL_CFG__CTLCFG_DENALI_PI_3 access per field reset 0x11387
  [24] PI_NORMAL_LVL_SEQ rw — Enable the PI to finish all the pending leveling before releasing the DFI bus.
  [16] PI_RELEASE_DFI ro — This is a status whether PI has release DFI. READ-ONLY.
  [15:0] PI_ID ro — Holds the PI ID number. This is a Cadence DDR PHY IP identifier. It is set to 0x1387. READ-ONLY
0x2010 CTLPHY_WRAP__CTL_CFG__CTLCFG_DENALI_PI_4
  [31:16] PI_TCMD_GAP — Specifies the minimum gap in DFI clocks between two commands. Used to guard the timing from the last command of MC and the first command of PI when MC hand over the control of DFI to PI.
  [9:8] PI_NOTCARE_PHYUPD — Allow the PI to issue a controller request to the controller if a phyupd_req from the PHY has been detected.bit[1] represents supports in normal state;bit[0] represents supports in initialization state. Set to 1 to issue the controller request.
  [0] PI_INIT_LVL_EN — Enables the initial leveling sequence after PI initialization procedure. Set to 1 to enable.
0x2014 CTLPHY_WRAP__CTL_CFG__CTLCFG_DENALI_PI_5 access per field
  [25:24] PI_DFI_PHYMSTR_TYPE rw — DFI Controller Request Type used for dfi 4.1 verision: This signal indicates the required state of DRAM when PHY becomes the controller. Each memory rank uses one bit. 1'b0: IDLE. The MC should close all the pages. 1'b1: IDLE or Self Refresh.
  [16] PI_DFI_VERSION rw — Define the DFI controller version, set 1 for DFI4.1, set 0 for DFI4.0
  [8] PI_TRAIN_ALL_FREQ_REQ wo — Triggers training for all supported frequencies in PI_FREQ_MAP. Applies to LPDDR4 devices onlyh. Set to 1 to trigger. Only applicable after memory initialization has been completed. Can be used to train new frequencies that were not available at initialization time. WRITE-ONLY
0x2018 CTLPHY_WRAP__CTL_CFG__CTLCFG_DENALI_PI_6
  [8] PI_DFI_PHYMSTR_STATE_SEL_R — DFI PHY Controller State Select: Indication from the PHY to the MC whether the requested memory state is IDLE or Self refresh. 'b0: indicates that the corresponding CS must be put into the IDLE state. 'b1: indicates that the corresponding CS must be put into the Self refresh state.
  [0] PI_DFI_PHYMSTR_CS_STATE_R — This signal indicates the state of the DRAM when the PHY becomes the controller. 'b0: The PHY specifies the required state, using the dfi_phymstr_state_sel signal. 'b1: is reserved.
0x201C CTLPHY_WRAP__CTL_CFG__CTLCFG_DENALI_PI_7 ro
  [31:0] PI_TDFI_PHYMSTR_MAX — Indicates the maximum number of DFI clock cycles registered while the dfi_phymstr_req signal is asserted and the dfi_phymstr_ack signal is asserted. READ-ONLY.
0x2020 CTLPHY_WRAP__CTL_CFG__CTLCFG_DENALI_PI_8 ro
  [19:0] PI_TDFI_PHYMSTR_RESP — Indicates the maximum number of DFI clock cycles registered between a dfi_phymstr_req signal assertion and a dfi_phymstr_ack signal assertion. READ-ONLY
0x2024 CTLPHY_WRAP__CTL_CFG__CTLCFG_DENALI_PI_9 ro
  [19:0] PI_TDFI_PHYUPD_RESP — Indicates the maximum number of DFI clock cycles registered between a dfi_phyupd_req signal assertion and a dfi_phyupd_ack signal assertion. READ-ONLY.
0x2028 CTLPHY_WRAP__CTL_CFG__CTLCFG_DENALI_PI_10 ro
  [31:0] PI_TDFI_PHYUPD_MAX — Indicates the maximum number of DFI clock cycles registered while the dfi_phyupd_req signal is asserted and the dfi_phy_ack signal is asserted. READ-ONLY.
0x202C CTLPHY_WRAP__CTL_CFG__CTLCFG_DENALI_PI_11
  [8] PI_INIT_DFS_CALVL_ONLY — Enables frequency training for CA leveling only. Other trainings are not performed.
  [4:0] PI_INIT_WORK_FREQ — Indicates the initial work frequency after initialization and initial leveling sequence.
0x2030 CTLPHY_WRAP__CTL_CFG__CTLCFG_DENALI_PI_12
  [31:0] PI_FREQ_MAP — Frequency map for supported working frequencies. Each bit represents one supported frequency.
0x2034 CTLPHY_WRAP__CTL_CFG__CTLCFG_DENALI_PI_13 reset 0xF0001
  [24] PI_SWLVL_CS_SEL — Defines which chip selects are active in swlvl, 0 for binary, 1 for one-hot.
  [19:16] PI_CS_MAP — Defines which chip selects are active.
  [0] PI_SW_RST_N — User request to reset the whole PI except the parameter modules. Set 0 to reset, set to 1 to release.
0x2038 CTLPHY_WRAP__CTL_CFG__CTLCFG_DENALI_PI_14
  [27:24] PI_TMRR — DRAM tMRR value in memory clock cycles.
  [16] PI_SRX_LVL_TARGET_CS_EN — Defines self refresh exit trigger target rank/ranks training or all ranks training. 1: The rank/ranks exit from self refresh will trigger the corresponding rank/ranks training. Note: If multiple ranks exit from self refresh, current design only support the multiple ranks srx command issues at the same time. 0: Any rank/ranks exit from self refresh will trigger all ranks training
  [12:8] PI_RANK_NUM_PER_CKE — Defines the number of chip selects share one cke
  [3:0] PI_CS_MASK — Defines which chip selects are active.
0x203C CTLPHY_WRAP__CTL_CFG__CTLCFG_DENALI_PI_15
  [16] PI_MCAREF_FORWARD_ONLY — Controls the generation of AREF from the PI module or forward the MC received value.
  [10:8] PI_VRCG_EN — Whether enable VRCG mode in two cases: bit0 - when DFS. bit1-when setting DQ Vref. bit2-when setting CBT.
  [3:0] PI_TMPRR — DRAM tMPRR value in memory clock cycles.
0x2040 CTLPHY_WRAP__CTL_CFG__CTLCFG_DENALI_PI_16 access per field
  [24] PI_ON_DFIBUS ro — Monitors the state of the PI controlling the DFI bus. 1 means PI is in control. READ-ONLY.
  [19:0] PI_TREF_INTERVAL rw — Defines the cycles between refreshes to different chip selects.
0x2044 CTLPHY_WRAP__CTL_CFG__CTLCFG_DENALI_PI_17 access per field
  [24] PI_SW_WRLVL_RESP_0 ro — Write leveling response for data slice 0. READ-ONLY
  [16] PI_SWLVL_OP_DONE ro — Reports the status of the software leveling operation. Value of 1 indicates operation complete. READ-ONLY
  [8] PI_SWLVL_LOAD wo — User request to load delays and execute software leveling. Set to 1 to trigger. WRITE-ONLY
  [0] PI_DATA_RETENTION ro — Monitors the readiness for the PHY to be put into data retention mode after pi_sref_entry req parameter has been written. 1 means ready for data retention. READ-ONLY.
0x2048 CTLPHY_WRAP__CTL_CFG__CTLCFG_DENALI_PI_18 ro
  [25:24] PI_SW_RDLVL_RESP_0 — Read leveling response for data slice 0. READ-ONLY
  [16] PI_SW_WRLVL_RESP_3 — Write leveling response for data slice 3. READ-ONLY
  [8] PI_SW_WRLVL_RESP_2 — Write leveling response for data slice 2. READ-ONLY
  [0] PI_SW_WRLVL_RESP_1 — Write leveling response for data slice 1. READ-ONLY
0x204C CTLPHY_WRAP__CTL_CFG__CTLCFG_DENALI_PI_19 ro
  [25:24] PI_SW_CALVL_RESP_0 — CA leveling response for address slice 0. READ-ONLY
  [17:16] PI_SW_RDLVL_RESP_3 — Read leveling response for data slice 3. READ-ONLY
  [9:8] PI_SW_RDLVL_RESP_2 — Read leveling response for data slice 2. READ-ONLY
  [1:0] PI_SW_RDLVL_RESP_1 — Read leveling response for data slice 1. READ-ONLY
0x2050 CTLPHY_WRAP__CTL_CFG__CTLCFG_DENALI_PI_20 access per field
  [24] PI_SWLVL_WR_SLICE_0 wo — SW leveling write command in WDQ training. WRITE-ONLY
  [16] PI_SWLVL_EXIT wo — User request to exit software leveling. Set to 1 to exit. WRITE-ONLY
  [8] PI_SWLVL_START wo — User request to initiate software leveling of type in the SW_LEVELING_MODE parameter. Set to 1 to trigger. WRITE-ONLY
  [2:0] PI_SW_LEVELING_MODE rw — Defines the leveling operation for software leveling. Set to 'b111 for DDR4 VREF training, set to b001 for write leveling, set to b010 for read data eye training, or set to b011 for read gate training, set to b100 for ca training, set to b101 for wdq training.
{0x2000+4i} CTLPHY_WRAP__CTL_CFG__CTLCFG_DENALI_PI_{i} access per field (i=21..23)
  [24] PI_SWLVL_WR_SLICE_{i-20} wo — SW leveling write command in WDQ training. WRITE-ONLY
  [17:16] PI_SW_WDQLVL_RESP_{i-21} ro — Leveling response for data slice {i-21}. READ-ONLY
  [8] PI_SWLVL_VREF_UPDATE_SLICE_{i-21} wo — SW leveling vref update command in WDQ training. WRITE-ONLY
  [0] PI_SWLVL_RD_SLICE_{i-21} wo — SW leveling read command in WDQ training. WRITE-ONLY
